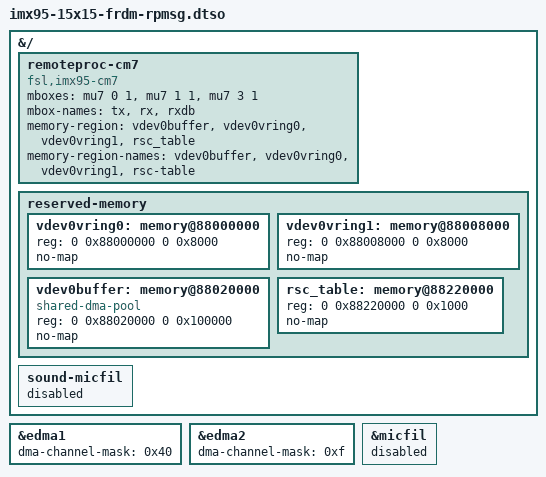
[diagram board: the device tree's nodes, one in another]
// SPDX-License-Identifier: (GPL-2.0+ OR MIT)
/*
 * Copyright 2026 NXP
 *
 * This DT overlay is meant to be used alongside the mx95evkrpmsg SM
 * configuration for remoteproc and audio over rpmsg.
 */

/dts-v1/;
/plugin/;

&{/} {
	remoteproc-cm7 {
		compatible = "fsl,imx95-cm7";
		mboxes = <&mu7 0 1>, <&mu7 1 1>, <&mu7 3 1>;
		mbox-names = "tx", "rx", "rxdb";
		memory-region = <&vdev0buffer>, <&vdev0vring0>,
				<&vdev0vring1>, <&rsc_table>;
		memory-region-names = "vdev0buffer", "vdev0vring0",
				      "vdev0vring1", "rsc-table";
	};

	reserved-memory {
		#address-cells = <2>;
		#size-cells = <2>;

		vdev0vring0: memory@88000000 {
			reg = <0 0x88000000 0 0x8000>;
			no-map;
		};

		vdev0vring1: memory@88008000 {
			reg = <0 0x88008000 0 0x8000>;
			no-map;
		};

		vdev0buffer: memory@88020000 {
			compatible = "shared-dma-pool";
			reg = <0 0x88020000 0 0x100000>;
			no-map;
		};

		rsc_table: memory@88220000 {
			reg = <0 0x88220000 0 0x1000>;
			no-map;
		};
	};

	sound-micfil {
		status = "disabled";
	};
};

&edma1 {
	/* reserved for M7 */
	dma-channel-mask = <0x40>;
};

&edma2 {
	/* reserved for M7 and V2X */
	dma-channel-mask = <0xf>;
};

&micfil {
	/* reserved for M7 */
	status = "reserved";
};
